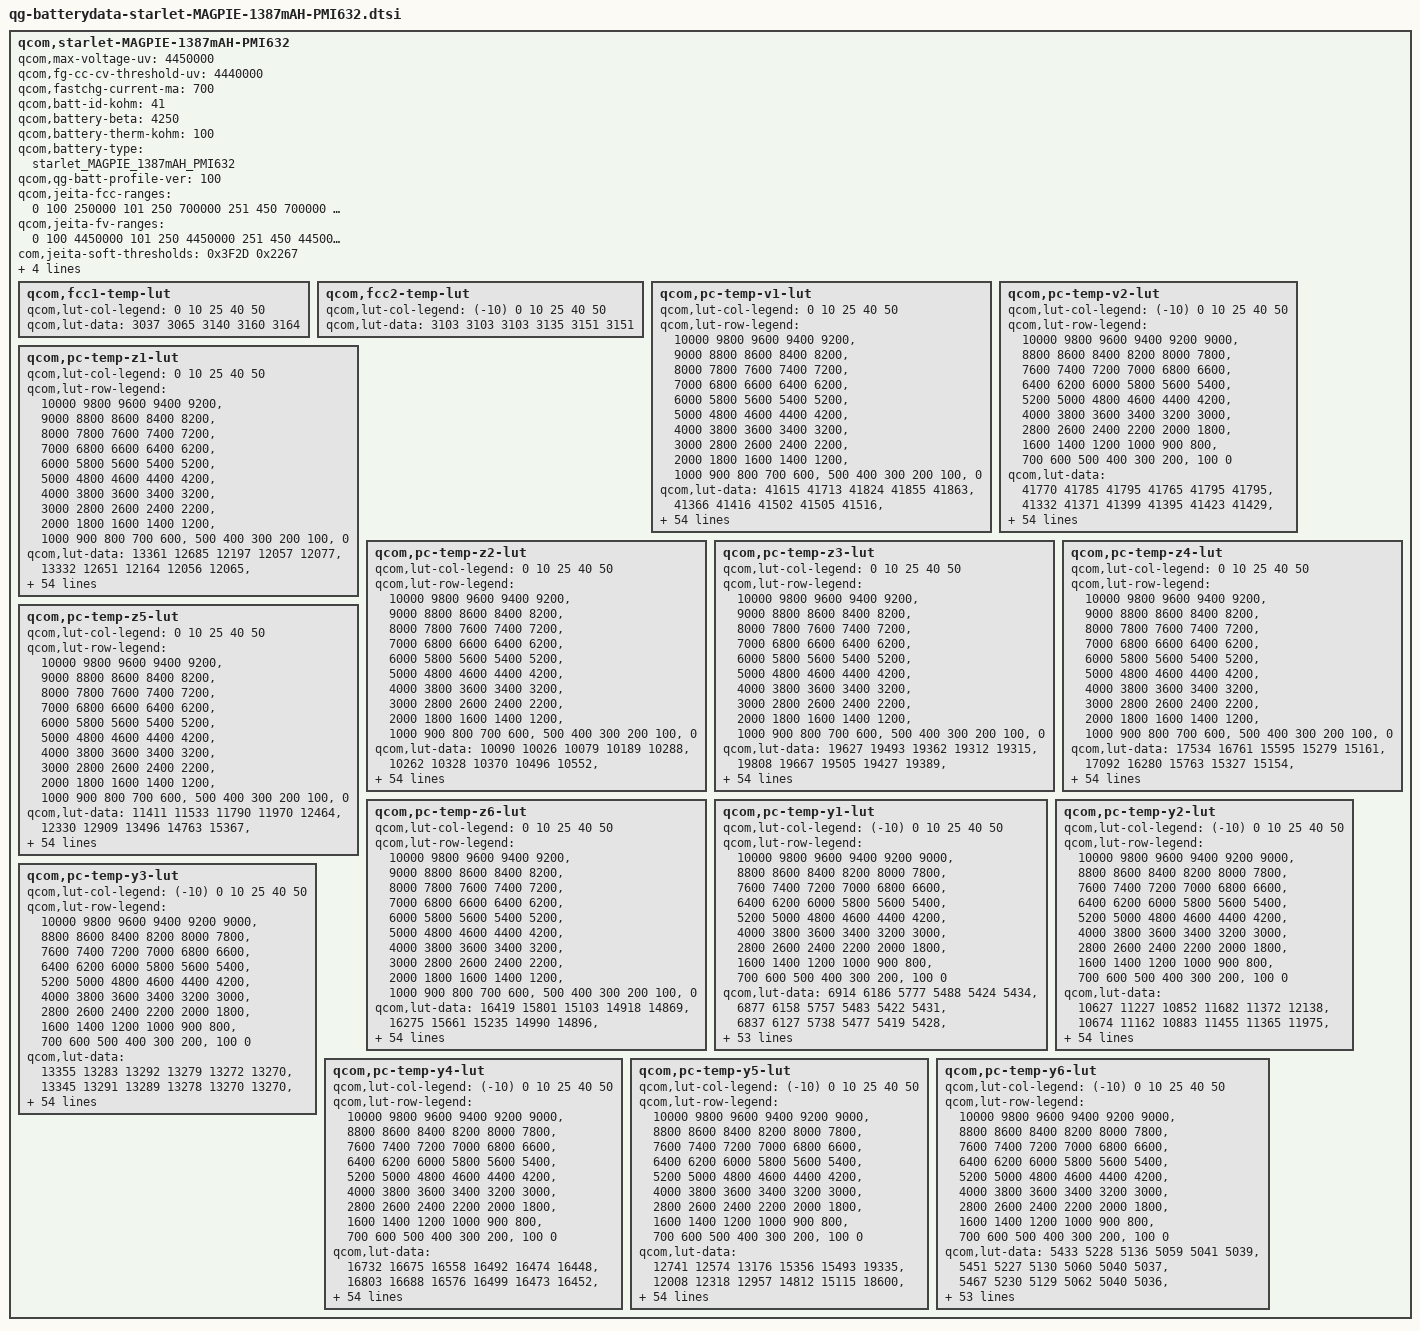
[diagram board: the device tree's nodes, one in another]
qcom,starlet-MAGPIE-1387mAH-PMI632 {
	qcom,max-voltage-uv = <4450000>;
	qcom,fg-cc-cv-threshold-uv = <4440000>;
	qcom,fastchg-current-ma = <700>; // Assumed 0.5C default until step charging takes over
	qcom,batt-id-kohm = <41>; // 220K on board in parallel with 100K on pack and 100K on flex
	qcom,battery-beta = <4250>; // Assumes 25/50 Beta for NCP03WF104F05RL / NTCG064EF104FT
	qcom,battery-therm-kohm = <100>; // // Assumes 100K for NCP03WF104F05RL / NTCG064EF104FT
	qcom,battery-type = "starlet_MAGPIE_1387mAH_PMI632";
	qcom,qg-batt-profile-ver = <100>;

    /*
     * array of 3-tuples in which a 3-tuple describes a range
     *        data of sw-jeita FCC (full charging current) setting.
     * [0]: the low threshold of battery temperature in deci-degree;
     * [1]: the high threshold of battery temperature in deci-degree;
     * [2]: the FCC in uA when battery temperature falls between the low and high thresholds.
     */
	qcom,jeita-fcc-ranges = <0  100 250000
				101 250 700000
				251 450 700000
				451 600 700000>; // Not clear how to specify step charging

	qcom,jeita-fv-ranges = <0  100 4450000
				101 250 4450000
				251 450 4450000
				451 600 4200000>;

	/*
	 * JEITA ADC values are calculated as follows, assuming
	 * a 30K pull-up. r_therm comes from the NTCG063JF103FTB
	 * thermistor datasheet.
	 *   v_adc = v_pull / (r_pullup + r_therm) * r_therm
	 *   v_adc = 1.8 / (30K + r_therm) * r_therm
	 *   adc_code = v_adc * v_fullscale / v_ref
	 *   adc_code = v_adc * 28900 / 1875
	 */
	/* COOL = 20 degC, WARM = 43 degC, need to change to 25C and 45C */
    com,jeita-soft-thresholds = <0x3F2D 0x2267>;
	/* COLD = 0 degC, HOT = 45 degC, need to change to 0C and 60C */
	qcom,jeita-hard-thresholds = <0x5830 0x20C5>;
	/* COOL hys = 23 degC, WARM hys = 42 degC, need to change to 28C and 44C */
    qcom,jeita-soft-hys-thresholds = <0x3BCF 0x247B>;
	qcom,jeita-soft-fcc-ua = <700000 700000>;
	qcom,jeita-soft-fv-uv = <4450000 4200000>;

	qcom,fcc1-temp-lut {
		qcom,lut-col-legend = <0 10 25 40 50>;
		qcom,lut-data = <3037 3065 3140 3160 3164>;
	};

	qcom,fcc2-temp-lut {
		qcom,lut-col-legend = <(-10) 0 10 25 40 50>;
		qcom,lut-data = <3103 3103 3103 3135 3151 3151>;
	};

	qcom,pc-temp-v1-lut {
		qcom,lut-col-legend = <0 10 25 40 50>;
		qcom,lut-row-legend = <10000 9800 9600 9400 9200>,
			<9000 8800 8600 8400 8200>,
			<8000 7800 7600 7400 7200>,
			<7000 6800 6600 6400 6200>,
			<6000 5800 5600 5400 5200>,
			<5000 4800 4600 4400 4200>,
			<4000 3800 3600 3400 3200>,
			<3000 2800 2600 2400 2200>,
			<2000 1800 1600 1400 1200>,
			<1000 900 800 700 600>,
			<500 400 300 200 100>,
			<0>;
		qcom,lut-data = <41615 41713 41824 41855 41863>,
			<41366 41416 41502 41505 41516>,
			<41211 41223 41275 41285 41292>,
			<41103 41110 41126 41142 41147>,
			<41009 41021 41036 41047 41052>,
			<40923 40936 40962 40971 40978>,
			<40834 40853 40870 40885 40894>,
			<40709 40746 40756 40773 40783>,
			<40537 40589 40616 40627 40637>,
			<40342 40393 40431 40441 40450>,
			<40139 40185 40212 40225 40235>,
			<39933 39974 39998 40005 40016>,
			<39739 39770 39793 39795 39808>,
			<39561 39588 39602 39604 39616>,
			<39392 39421 39426 39428 39437>,
			<39228 39264 39263 39264 39270>,
			<39069 39109 39106 39106 39110>,
			<38911 38954 38950 38948 38951>,
			<38748 38791 38788 38785 38788>,
			<38575 38620 38616 38612 38616>,
			<38392 38442 38435 38431 38435>,
			<38199 38251 38243 38238 38242>,
			<38000 38051 38027 38020 38025>,
			<37799 37842 37767 37736 37743>,
			<37601 37623 37474 37413 37422>,
			<37408 37388 37198 37161 37177>,
			<37222 37143 36971 36985 37017>,
			<37038 36917 36798 36844 36886>,
			<36854 36720 36673 36725 36763>,
			<36681 36566 36574 36623 36649>,
			<36525 36453 36485 36524 36540>,
			<36386 36361 36400 36424 36434>,
			<36273 36279 36316 36324 36332>,
			<36184 36202 36223 36226 36233>,
			<36103 36126 36125 36129 36134>,
			<36023 36044 36028 36029 36032>,
			<35946 35957 35935 35927 35926>,
			<35859 35862 35836 35816 35808>,
			<35761 35758 35721 35685 35671>,
			<35644 35638 35583 35531 35510>,
			<35497 35484 35413 35350 35323>,
			<35298 35274 35187 35123 35091>,
			<35069 35035 34931 34865 34832>,
			<34815 34775 34652 34582 34550>,
			<34563 34508 34373 34312 34288>,
			<34327 34255 34140 34096 34082>,
			<34243 34157 34053 34013 34002>,
			<34178 34082 33978 33940 33929>,
			<34095 34010 33909 33871 33861>,
			<34025 33939 33843 33796 33783>,
			<33928 33853 33741 33687 33668>,
			<33755 33687 33480 33392 33349>,
			<33320 33271 32951 32858 32834>,
			<32608 32557 32233 32164 32157>,
			<31577 31562 31207 31193 31221>,
			<30000 30000 30000 30000 30000>;
	};

	qcom,pc-temp-v2-lut {
		qcom,lut-col-legend = <(-10) 0 10 25 40 50>;
		qcom,lut-row-legend = <10000 9800 9600 9400 9200 9000>,
			<8800 8600 8400 8200 8000 7800>,
			<7600 7400 7200 7000 6800 6600>,
			<6400 6200 6000 5800 5600 5400>,
			<5200 5000 4800 4600 4400 4200>,
			<4000 3800 3600 3400 3200 3000>,
			<2800 2600 2400 2200 2000 1800>,
			<1600 1400 1200 1000 900 800>,
			<700 600 500 400 300 200>,
			<100 0>;
		qcom,lut-data = <41770 41785 41795 41765 41795 41795>,
			<41332 41371 41399 41395 41423 41429>,
			<41005 41062 41099 41115 41141 41152>,
			<40849 40909 40947 40968 40992 41003>,
			<40775 40834 40868 40889 40911 40921>,
			<40706 40765 40797 40814 40834 40843>,
			<40611 40669 40704 40715 40735 40744>,
			<40497 40556 40598 40600 40622 40630>,
			<40353 40416 40464 40454 40477 40484>,
			<40148 40225 40272 40255 40276 40282>,
			<39912 40010 40054 40038 40057 40061>,
			<39681 39808 39844 39830 39848 39851>,
			<39443 39610 39632 39624 39640 39642>,
			<39221 39423 39439 39435 39450 39453>,
			<39023 39253 39271 39268 39279 39284>,
			<38839 39084 39114 39108 39116 39122>,
			<38660 38887 38961 38949 38957 38962>,
			<38486 38662 38810 38792 38801 38804>,
			<38308 38432 38632 38628 38637 38638>,
			<38119 38208 38394 38459 38464 38466>,
			<37923 37986 38117 38275 38280 38284>,
			<37720 37768 37853 38047 38069 38074>,
			<37511 37554 37611 37758 37814 37820>,
			<37304 37348 37388 37464 37542 37550>,
			<37102 37151 37185 37211 37270 37286>,
			<36907 36962 36996 36999 37036 37057>,
			<36730 36790 36827 36829 36861 36883>,
			<36575 36637 36677 36683 36718 36738>,
			<36436 36500 36543 36553 36590 36608>,
			<36311 36376 36422 36436 36473 36491>,
			<36199 36263 36314 36330 36367 36385>,
			<36093 36157 36212 36230 36266 36285>,
			<35988 36056 36113 36134 36168 36191>,
			<35882 35959 36015 36040 36069 36095>,
			<35769 35860 35916 35945 35966 35993>,
			<35647 35759 35814 35848 35859 35878>,
			<35515 35655 35711 35749 35740 35742>,
			<35367 35545 35600 35636 35608 35589>,
			<35199 35427 35480 35504 35458 35426>,
			<35004 35292 35343 35345 35289 35256>,
			<34792 35118 35175 35156 35102 35074>,
			<34578 34879 34954 34934 34890 34867>,
			<34374 34589 34685 34673 34631 34614>,
			<34192 34300 34382 34338 34319 34306>,
			<34009 34027 34080 34072 34074 34067>,
			<33789 33826 33878 33898 33902 33899>,
			<33671 33733 33790 33819 33829 33831>,
			<33553 33640 33703 33745 33755 33759>,
			<33431 33542 33616 33665 33677 33680>,
			<33284 33414 33516 33561 33573 33577>,
			<33064 33198 33346 33353 33355 33374>,
			<32675 32768 32959 32867 32892 32927>,
			<32097 32131 32325 32193 32267 32323>,
			<31375 31346 31525 31398 31526 31595>,
			<30529 30407 30595 30493 30691 30786>,
			<29490 29308 29749 29512 29716 29867>;
	};

	qcom,pc-temp-z1-lut {
		qcom,lut-col-legend = <0 10 25 40 50>;
		qcom,lut-row-legend = <10000 9800 9600 9400 9200>,
			<9000 8800 8600 8400 8200>,
			<8000 7800 7600 7400 7200>,
			<7000 6800 6600 6400 6200>,
			<6000 5800 5600 5400 5200>,
			<5000 4800 4600 4400 4200>,
			<4000 3800 3600 3400 3200>,
			<3000 2800 2600 2400 2200>,
			<2000 1800 1600 1400 1200>,
			<1000 900 800 700 600>,
			<500 400 300 200 100>,
			<0>;
		qcom,lut-data = <13361 12685 12197 12057 12077>,
			<13332 12651 12164 12056 12065>,
			<13292 12616 12145 12048 12061>,
			<13244 12584 12131 12041 12060>,
			<13199 12554 12122 12036 12057>,
			<13156 12526 12114 12031 12054>,
			<13116 12498 12105 12027 12051>,
			<13077 12472 12095 12024 12048>,
			<13037 12447 12086 12022 12046>,
			<12996 12426 12080 12019 12045>,
			<12956 12410 12075 12018 12045>,
			<12920 12396 12073 12018 12045>,
			<12893 12386 12072 12019 12045>,
			<12875 12381 12072 12019 12044>,
			<12862 12381 12072 12018 12044>,
			<12853 12382 12072 12018 12045>,
			<12850 12382 12072 12018 12045>,
			<12852 12383 12073 12019 12045>,
			<12860 12384 12073 12019 12046>,
			<12867 12386 12074 12020 12047>,
			<12874 12390 12075 12020 12047>,
			<12881 12393 12078 12022 12049>,
			<12891 12396 12080 12024 12050>,
			<12901 12400 12081 12025 12052>,
			<12909 12404 12083 12027 12053>,
			<12918 12408 12084 12028 12055>,
			<12927 12412 12086 12030 12057>,
			<12937 12416 12088 12032 12058>,
			<12947 12418 12090 12034 12059>,
			<12956 12421 12092 12036 12060>,
			<12962 12423 12095 12039 12062>,
			<12968 12427 12098 12042 12065>,
			<12974 12432 12103 12045 12069>,
			<12981 12437 12108 12047 12071>,
			<12989 12444 12115 12050 12072>,
			<13003 12453 12122 12053 12074>,
			<13022 12467 12129 12057 12076>,
			<13049 12485 12137 12062 12079>,
			<13088 12508 12148 12068 12083>,
			<13138 12538 12162 12075 12089>,
			<13197 12574 12178 12084 12096>,
			<13268 12621 12197 12096 12105>,
			<13354 12675 12220 12109 12116>,
			<13464 12737 12247 12125 12128>,
			<13596 12829 12288 12148 12144>,
			<13679 12892 12323 12171 12163>,
			<13710 12912 12339 12181 12171>,
			<13740 12935 12358 12192 12181>,
			<13786 12960 12370 12205 12191>,
			<13810 12988 12388 12217 12200>,
			<13845 13012 12408 12231 12211>,
			<13917 13048 12429 12248 12226>,
			<13950 13099 12455 12284 12240>,
			<14029 13131 12493 12293 12264>,
			<14029 13131 12493 12293 12264>,
			<14029 13131 12493 12293 12264>;
	};

	qcom,pc-temp-z2-lut {
		qcom,lut-col-legend = <0 10 25 40 50>;
		qcom,lut-row-legend = <10000 9800 9600 9400 9200>,
			<9000 8800 8600 8400 8200>,
			<8000 7800 7600 7400 7200>,
			<7000 6800 6600 6400 6200>,
			<6000 5800 5600 5400 5200>,
			<5000 4800 4600 4400 4200>,
			<4000 3800 3600 3400 3200>,
			<3000 2800 2600 2400 2200>,
			<2000 1800 1600 1400 1200>,
			<1000 900 800 700 600>,
			<500 400 300 200 100>,
			<0>;
		qcom,lut-data = <10090 10026 10079 10189 10288>,
			<10262 10328 10370 10496 10552>,
			<10367 10459 10610 11089 11207>,
			<10441 10523 10724 11623 11861>,
			<10470 10559 10778 11794 12114>,
			<10470 10566 10809 11739 12063>,
			<10466 10560 10816 11598 11897>,
			<10459 10543 10814 11418 11701>,
			<10447 10483 10807 11226 11517>,
			<10437 10411 10758 11038 11339>,
			<10456 10377 10686 10862 11103>,
			<10497 10369 10628 10737 10829>,
			<10525 10369 10527 10675 10621>,
			<10541 10388 10411 10609 10518>,
			<10555 10430 10405 10499 10505>,
			<10579 10470 10435 10451 10565>,
			<10605 10501 10416 10501 10649>,
			<10605 10531 10365 10551 10702>,
			<10572 10560 10380 10579 10740>,
			<10535 10585 10417 10592 10770>,
			<10511 10608 10446 10598 10789>,
			<10497 10633 10476 10606 10800>,
			<10495 10658 10543 10626 10815>,
			<10502 10685 10696 10754 10940>,
			<10516 10716 10901 10980 11183>,
			<10537 10755 10999 11124 11274>,
			<10563 10801 10987 11181 11093>,
			<10592 10831 10967 11205 10883>,
			<10628 10842 10972 11133 10866>,
			<10659 10852 10980 10964 10920>,
			<10675 10861 10940 10806 10908>,
			<10687 10870 10820 10655 10656>,
			<10693 10882 10740 10516 10386>,
			<10697 10909 10766 10429 10364>,
			<10702 10952 10812 10368 10431>,
			<10731 10978 10790 10353 10523>,
			<10787 10991 10695 10454 10690>,
			<10813 10986 10631 10612 10851>,
			<10780 10941 10735 10730 10884>,
			<10725 10880 10990 10837 10892>,
			<10693 10838 11103 10919 10893>,
			<10674 10807 11099 10983 10853>,
			<10675 10790 11084 10981 10786>,
			<10702 10767 11027 10690 10719>,
			<10922 10904 10979 10627 10676>,
			<10862 10803 10878 10545 10562>,
			<10899 10737 10766 10555 10475>,
			<11252 10634 10647 10377 10401>,
			<10622 10537 10537 10333 10450>,
			<10513 10427 10446 10335 10521>,
			<10436 10345 10459 10430 10622>,
			<10378 10289 10361 10130 10169>,
			<10328 10167 10128 10044 10017>,
			<10133 9996 9841 9841 9991>,
			<10133 9996 9841 9841 9991>,
			<10133 9996 9841 9841 9991>;
	};

	qcom,pc-temp-z3-lut {
		qcom,lut-col-legend = <0 10 25 40 50>;
		qcom,lut-row-legend = <10000 9800 9600 9400 9200>,
			<9000 8800 8600 8400 8200>,
			<8000 7800 7600 7400 7200>,
			<7000 6800 6600 6400 6200>,
			<6000 5800 5600 5400 5200>,
			<5000 4800 4600 4400 4200>,
			<4000 3800 3600 3400 3200>,
			<3000 2800 2600 2400 2200>,
			<2000 1800 1600 1400 1200>,
			<1000 900 800 700 600>,
			<500 400 300 200 100>,
			<0>;
		qcom,lut-data = <19627 19493 19362 19312 19315>,
			<19808 19667 19505 19427 19389>,
			<19829 19717 19536 19440 19402>,
			<19824 19698 19541 19436 19399>,
			<19822 19671 19528 19431 19392>,
			<19826 19661 19512 19434 19392>,
			<19836 19659 19512 19442 19398>,
			<19844 19659 19528 19454 19409>,
			<19847 19667 19543 19463 19420>,
			<19842 19685 19553 19466 19426>,
			<19806 19694 19563 19462 19420>,
			<19749 19688 19559 19448 19402>,
			<19697 19673 19509 19426 19375>,
			<19649 19636 19445 19397 19351>,
			<19624 19575 19417 19367 19338>,
			<19639 19527 19401 19346 19333>,
			<19664 19509 19378 19335 19327>,
			<19657 19501 19353 19326 19321>,
			<19637 19495 19345 19321 19314>,
			<19619 19484 19344 19318 19310>,
			<19610 19468 19344 19318 19309>,
			<19607 19461 19345 19323 19312>,
			<19605 19469 19357 19330 19318>,
			<19601 19490 19397 19348 19334>,
			<19602 19520 19446 19373 19353>,
			<19613 19556 19465 19383 19358>,
			<19631 19585 19460 19378 19346>,
			<19661 19593 19450 19368 19330>,
			<19701 19589 19435 19346 19320>,
			<19721 19580 19412 19319 19314>,
			<19721 19564 19383 19311 19315>,
			<19716 19540 19349 19330 19326>,
			<19704 19513 19330 19352 19336>,
			<19679 19475 19355 19354 19336>,
			<19649 19445 19412 19346 19329>,
			<19612 19442 19432 19337 19322>,
			<19571 19450 19401 19330 19316>,
			<19554 19460 19369 19325 19313>,
			<19566 19466 19374 19325 19313>,
			<19591 19474 19399 19326 19314>,
			<19623 19489 19412 19330 19315>,
			<19664 19519 19412 19349 19321>,
			<19674 19533 19412 19360 19325>,
			<19661 19534 19413 19351 19325>,
			<19555 19479 19405 19343 19322>,
			<19565 19489 19408 19350 19325>,
			<19578 19506 19420 19359 19333>,
			<19597 19517 19438 19356 19329>,
			<19600 19536 19447 19351 19325>,
			<19613 19546 19431 19347 19315>,
			<19640 19555 19432 19343 19314>,
			<19671 19577 19491 19374 19357>,
			<19726 19622 19556 19424 19368>,
			<19768 19708 19527 19402 19347>,
			<19768 19708 19527 19402 19347>,
			<19768 19708 19527 19402 19347>;
	};

	qcom,pc-temp-z4-lut {
		qcom,lut-col-legend = <0 10 25 40 50>;
		qcom,lut-row-legend = <10000 9800 9600 9400 9200>,
			<9000 8800 8600 8400 8200>,
			<8000 7800 7600 7400 7200>,
			<7000 6800 6600 6400 6200>,
			<6000 5800 5600 5400 5200>,
			<5000 4800 4600 4400 4200>,
			<4000 3800 3600 3400 3200>,
			<3000 2800 2600 2400 2200>,
			<2000 1800 1600 1400 1200>,
			<1000 900 800 700 600>,
			<500 400 300 200 100>,
			<0>;
		qcom,lut-data = <17534 16761 15595 15279 15161>,
			<17092 16280 15763 15327 15154>,
			<16712 15957 15472 15171 15054>,
			<16389 15745 15269 15058 14972>,
			<16158 15597 15196 14999 14924>,
			<15995 15498 15146 14959 14894>,
			<15865 15425 15095 14924 14867>,
			<15749 15360 15040 14888 14838>,
			<15647 15291 14987 14853 14805>,
			<15568 15220 14934 14824 14778>,
			<15509 15153 14886 14804 14766>,
			<15461 15095 14861 14791 14766>,
			<15420 15054 14875 14786 14767>,
			<15382 15037 14902 14792 14771>,
			<15337 15032 14903 14801 14769>,
			<15245 15028 14891 14802 14756>,
			<15143 15018 14885 14792 14739>,
			<15101 14991 14882 14777 14727>,
			<15086 14965 14871 14763 14717>,
			<15078 14952 14849 14746 14705>,
			<15069 14943 14826 14731 14694>,
			<15058 14933 14808 14719 14687>,
			<15047 14908 14796 14716 14685>,
			<15037 14872 14794 14758 14728>,
			<15024 14847 14815 14843 14820>,
			<15003 14840 14865 14889 14866>,
			<14975 14855 14928 14898 14868>,
			<14947 14893 14958 14903 14868>,
			<14926 14946 14963 14908 14866>,
			<14921 14979 14963 14912 14854>,
			<14933 14985 14966 14907 14833>,
			<14960 14986 14973 14866 14793>,
			<14979 14989 14975 14809 14750>,
			<14987 14995 14928 14779 14727>,
			<14996 14999 14831 14760 14711>,
			<15008 14987 14789 14749 14706>,
			<15023 14943 14791 14740 14708>,
			<15028 14899 14794 14735 14711>,
			<14999 14868 14786 14743 14718>,
			<14952 14846 14771 14769 14737>,
			<14931 14843 14770 14787 14752>,
			<14936 14875 14824 14787 14759>,
			<14951 14903 14866 14791 14767>,
			<14965 14914 14875 14817 14782>,
			<14920 14877 14844 14809 14778>,
			<14943 14896 14842 14798 14767>,
			<14953 14904 14836 14782 14747>,
			<14926 14904 14811 14767 14729>,
			<14948 14883 14779 14741 14705>,
			<14926 14858 14768 14719 14692>,
			<14915 14845 14770 14728 14702>,
			<14946 14880 14800 14779 14716>,
			<15030 14954 14803 14746 14717>,
			<15082 14946 14842 14768 14730>,
			<15082 14946 14842 14768 14730>,
			<15082 14946 14842 14768 14730>;
	};

	qcom,pc-temp-z5-lut {
		qcom,lut-col-legend = <0 10 25 40 50>;
		qcom,lut-row-legend = <10000 9800 9600 9400 9200>,
			<9000 8800 8600 8400 8200>,
			<8000 7800 7600 7400 7200>,
			<7000 6800 6600 6400 6200>,
			<6000 5800 5600 5400 5200>,
			<5000 4800 4600 4400 4200>,
			<4000 3800 3600 3400 3200>,
			<3000 2800 2600 2400 2200>,
			<2000 1800 1600 1400 1200>,
			<1000 900 800 700 600>,
			<500 400 300 200 100>,
			<0>;
		qcom,lut-data = <11411 11533 11790 11970 12464>,
			<12330 12909 13496 14763 15367>,
			<12887 13666 14644 15428 16297>,
			<13273 13967 15113 15681 16423>,
			<13587 14173 15216 15830 16389>,
			<13870 14331 15291 16282 16664>,
			<14131 14454 15455 16928 17212>,
			<14344 14585 15720 17526 18046>,
			<14493 14792 16038 18155 19237>,
			<14540 15207 16630 18659 20111>,
			<14418 15636 17648 18886 20152>,
			<14214 15920 18006 18815 19222>,
			<14039 15995 16670 18377 17585>,
			<13897 15700 14874 17013 16102>,
			<13882 14980 14368 15376 15372>,
			<14628 14383 14261 14525 15440>,
			<15604 14273 13873 14336 15580>,
			<15780 14450 13321 14253 15449>,
			<15661 14673 13262 14248 15243>,
			<15502 14737 13477 14430 15304>,
			<15494 14709 13776 14916 15799>,
			<15643 14786 14175 15891 17092>,
			<15821 15396 16947 17615 19518>,
			<16005 17039 27190 23737 25139>,
			<16287 20476 40274 32848 31569>,
			<16972 27739 44509 35607 32541>,
			<18375 36563 39959 30657 26659>,
			<21637 40442 33789 24087 19409>,
			<28321 39907 28071 19089 15795>,
			<33725 37898 22849 15180 13814>,
			<34854 33756 18760 13844 13278>,
			<34769 28462 15604 13982 13881>,
			<33328 24098 13964 14297 14900>,
			<29210 20065 14645 14748 15897>,
			<24399 17117 16793 15307 16802>,
			<20687 16254 17744 15733 17221>,
			<17545 15977 16943 16295 17456>,
			<16305 15909 16083 16834 17596>,
			<16789 16491 17126 16770 17286>,
			<18024 17916 20669 16258 16218>,
			<20149 19602 22387 15907 15446>,
			<24030 21772 19461 16137 15226>,
			<25506 22188 16690 16065 15018>,
			<24140 20992 16159 14782 14388>,
			<23526 20341 16729 14724 14345>,
			<23417 20107 16873 15022 14532>,
			<22635 20132 17047 15430 15075>,
			<22438 19678 18183 15403 15362>,
			<22034 20540 20082 15982 16079>,
			<22203 21728 19986 17502 16921>,
			<23594 22811 20708 17161 16241>,
			<23292 22010 20190 14885 16248>,
			<21108 17999 20379 19180 16786>,
			<17625 18473 18104 15904 15653>,
			<17625 18473 18104 15904 15653>,
			<17625 18473 18104 15904 15653>;
	};

	qcom,pc-temp-z6-lut {
		qcom,lut-col-legend = <0 10 25 40 50>;
		qcom,lut-row-legend = <10000 9800 9600 9400 9200>,
			<9000 8800 8600 8400 8200>,
			<8000 7800 7600 7400 7200>,
			<7000 6800 6600 6400 6200>,
			<6000 5800 5600 5400 5200>,
			<5000 4800 4600 4400 4200>,
			<4000 3800 3600 3400 3200>,
			<3000 2800 2600 2400 2200>,
			<2000 1800 1600 1400 1200>,
			<1000 900 800 700 600>,
			<500 400 300 200 100>,
			<0>;
		qcom,lut-data = <16419 15801 15103 14918 14869>,
			<16275 15661 15235 14990 14896>,
			<16107 15538 15131 14941 14869>,
			<15933 15426 15046 14887 14831>,
			<15807 15337 15002 14856 14806>,
			<15723 15281 14972 14840 14792>,
			<15658 15241 14951 14828 14783>,
			<15602 15209 14935 14819 14776>,
			<15553 15181 14920 14810 14770>,
			<15502 15156 14905 14800 14762>,
			<15448 15130 14890 14787 14752>,
			<15393 15102 14872 14773 14740>,
			<15345 15072 14850 14760 14728>,
			<15300 15040 14831 14746 14717>,
			<15261 15009 14815 14734 14707>,
			<15227 14985 14801 14722 14698>,
			<15197 14967 14787 14711 14688>,
			<15174 14952 14773 14700 14679>,
			<15159 14939 14760 14690 14670>,
			<15148 14927 14750 14681 14662>,
			<15141 14915 14741 14676 14658>,
			<15136 14907 14735 14674 14657>,
			<15131 14903 14735 14674 14659>,
			<15127 14902 14751 14702 14685>,
			<15125 14903 14790 14754 14735>,
			<15123 14914 14826 14777 14758>,
			<15122 14939 14846 14777 14753>,
			<15125 14965 14853 14775 14746>,
			<15136 14983 14849 14770 14738>,
			<15148 14991 14837 14759 14732>,
			<15158 14987 14824 14749 14724>,
			<15165 14976 14813 14741 14715>,
			<15166 14964 14802 14732 14704>,
			<15159 14951 14794 14722 14694>,
			<15148 14937 14787 14710 14683>,
			<15139 14925 14778 14700 14677>,
			<15129 14914 14763 14693 14674>,
			<15125 14906 14751 14688 14673>,
			<15127 14904 14750 14690 14675>,
			<15133 14903 14756 14702 14684>,
			<15147 14911 14768 14715 14693>,
			<15188 14949 14795 14727 14701>,
			<15226 14984 14817 14738 14709>,
			<15253 15005 14829 14748 14719>,
			<15228 14986 14820 14744 14717>,
			<15268 15018 14829 14747 14719>,
			<15289 15039 14837 14748 14716>,
			<15302 15053 14839 14743 14709>,
			<15319 15061 14836 14733 14698>,
			<15327 15064 14827 14723 14689>,
			<15349 15072 14834 14728 14694>,
			<15398 15112 14886 14774 14731>,
			<15482 15185 14933 14795 14743>,
			<15551 15242 14947 14801 14745>,
			<15551 15242 14947 14801 14745>,
			<15551 15242 14947 14801 14745>;
	};

	qcom,pc-temp-y1-lut {
		qcom,lut-col-legend = <(-10) 0 10 25 40 50>;
		qcom,lut-row-legend = <10000 9800 9600 9400 9200 9000>,
			<8800 8600 8400 8200 8000 7800>,
			<7600 7400 7200 7000 6800 6600>,
			<6400 6200 6000 5800 5600 5400>,
			<5200 5000 4800 4600 4400 4200>,
			<4000 3800 3600 3400 3200 3000>,
			<2800 2600 2400 2200 2000 1800>,
			<1600 1400 1200 1000 900 800>,
			<700 600 500 400 300 200>,
			<100 0>;
		qcom,lut-data = <6914 6186 5777 5488 5424 5434>,
			<6877 6158 5757 5483 5422 5431>,
			<6837 6127 5738 5477 5419 5428>,
			<6799 6097 5720 5470 5416 5425>,
			<6766 6072 5704 5464 5414 5423>,
			<6742 6054 5692 5461 5411 5421>,
			<6726 6045 5682 5459 5408 5421>,
			<6714 6039 5674 5459 5406 5421>,
			<6703 6031 5668 5457 5405 5421>,
			<6693 6019 5665 5455 5408 5420>,
			<6685 6009 5662 5454 5412 5419>,
			<6678 6004 5658 5453 5412 5419>,
			<6668 6002 5655 5452 5412 5419>,
			<6661 6000 5652 5451 5411 5419>,
			<6661 6000 5650 5451 5410 5418>,
			<6663 6000 5648 5451 5409 5418>,
			<6671 6001 5648 5451 5409 5418>,
			<6685 6002 5649 5452 5409 5420>,
			<6688 6003 5650 5453 5409 5422>,
			<6680 6002 5652 5454 5411 5424>,
			<6676 6003 5654 5454 5412 5425>,
			<6685 6003 5655 5456 5412 5424>,
			<6696 6002 5656 5457 5412 5422>,
			<6696 6001 5657 5459 5411 5422>,
			<6688 6001 5657 5459 5412 5423>,
			<6686 6005 5656 5459 5413 5425>,
			<6696 6010 5656 5459 5414 5425>,
			<6706 6016 5657 5458 5415 5424>,
			<6712 6020 5659 5457 5415 5424>,
			<6713 6023 5660 5457 5415 5425>,
			<6719 6025 5662 5459 5416 5429>,
			<6730 6029 5666 5462 5417 5431>,
			<6745 6036 5672 5466 5420 5431>,
			<6762 6045 5678 5469 5423 5431>,
			<6784 6054 5684 5471 5423 5432>,
			<6806 6065 5690 5472 5421 5432>,
			<6824 6081 5698 5474 5420 5433>,
			<6840 6102 5708 5476 5422 5433>,
			<6859 6125 5721 5482 5426 5435>,
			<6884 6150 5737 5490 5431 5437>,
			<6915 6176 5757 5498 5436 5441>,
			<6953 6199 5782 5508 5441 5446>,
			<6996 6223 5813 5521 5449 5453>,
			<7030 6259 5847 5541 5460 5459>,
			<7071 6304 5885 5565 5472 5469>,
			<7219 6342 5936 5595 5487 5483>,
			<7283 6377 5951 5611 5498 5488>,
			<7360 6410 5979 5633 5508 5494>,
			<7411 6448 5994 5655 5519 5501>,
			<7538 6498 6003 5673 5531 5511>,
			<7605 6565 6030 5693 5543 5521>,
			<7593 6647 6063 5712 5557 5525>,
			<7671 6680 6095 5738 5575 5540>,
			<7776 6763 6142 5766 5595 5553>,
			<7776 6763 6142 5766 5595 5553>,
			<7776 6763 6142 5766 5595 5553>;
	};

	qcom,pc-temp-y2-lut {
		qcom,lut-col-legend = <(-10) 0 10 25 40 50>;
		qcom,lut-row-legend = <10000 9800 9600 9400 9200 9000>,
			<8800 8600 8400 8200 8000 7800>,
			<7600 7400 7200 7000 6800 6600>,
			<6400 6200 6000 5800 5600 5400>,
			<5200 5000 4800 4600 4400 4200>,
			<4000 3800 3600 3400 3200 3000>,
			<2800 2600 2400 2200 2000 1800>,
			<1600 1400 1200 1000 900 800>,
			<700 600 500 400 300 200>,
			<100 0>;
		qcom,lut-data = <10627 11227 10852 11682 11372 12138>,
			<10674 11162 10883 11455 11365 11975>,
			<10720 11108 10924 11253 11333 11734>,
			<10763 11067 10967 11089 11280 11475>,
			<10805 11039 11004 10977 11210 11258>,
			<10843 11026 11028 10930 11127 11140>,
			<10880 11033 11042 10963 11003 11101>,
			<10915 11054 11064 11039 10872 11073>,
			<10940 11078 11094 11085 10850 11052>,
			<10958 11122 11138 11112 10962 11031>,
			<10976 11168 11192 11134 11084 11017>,
			<11002 11190 11262 11193 11136 11039>,
			<11032 11204 11356 11273 11175 11118>,
			<11056 11212 11424 11307 11187 11177>,
			<11072 11218 11459 11338 11264 11276>,
			<11088 11223 11479 11381 11367 11336>,
			<11109 11233 11471 11438 11423 11320>,
			<11138 11248 11440 11514 11477 11284>,
			<11165 11264 11421 11602 11498 11270>,
			<11184 11286 11416 11719 11510 11368>,
			<11201 11328 11413 11799 11531 11519>,
			<11224 11370 11424 11804 11658 11612>,
			<11256 11404 11472 11773 11872 11645>,
			<11290 11430 11536 11719 11918 11609>,
			<11320 11451 11592 11631 11696 11544>,
			<11348 11481 11648 11564 11469 11546>,
			<11370 11525 11705 11575 11481 11598>,
			<11385 11587 11758 11680 11714 11641>,
			<11397 11651 11807 11798 11907 11701>,
			<11404 11692 11840 11822 11938 11833>,
			<11408 11707 11860 11810 11947 11981>,
			<11405 11706 11876 11890 11968 12137>,
			<11389 11699 11893 12048 11972 12279>,
			<11351 11688 11913 12141 11959 12323>,
			<11299 11671 11917 12175 11988 12296>,
			<11253 11649 11902 12172 12004 12275>,
			<11216 11626 11886 12152 11982 12216>,
			<11178 11601 11866 12113 11898 12035>,
			<11115 11571 11831 12046 11746 11835>,
			<10996 11526 11773 11945 11559 11757>,
			<10809 11447 11696 11841 11479 11733>,
			<10494 11285 11588 11730 11517 11694>,
			<10078 10996 11411 11595 11583 11600>,
			<9838 10528 11045 11404 11626 11405>,
			<9667 10020 10519 11126 11403 11245>,
			<9656 9777 10213 10759 10962 11131>,
			<9655 9681 10090 10704 10906 11099>,
			<9654 9659 9960 10640 10830 11101>,
			<9653 9657 9799 10616 10869 11044>,
			<9653 9655 9706 10521 10922 10835>,
			<9653 9655 9673 10289 10664 10776>,
			<9652 9654 9661 10114 10562 10732>,
			<9652 9653 9657 10130 10551 10674>,
			<9652 9653 9656 10208 10612 10691>,
			<9652 9653 9656 10208 10612 10691>,
			<9652 9653 9656 10208 10612 10691>;
	};

	qcom,pc-temp-y3-lut {
		qcom,lut-col-legend = <(-10) 0 10 25 40 50>;
		qcom,lut-row-legend = <10000 9800 9600 9400 9200 9000>,
			<8800 8600 8400 8200 8000 7800>,
			<7600 7400 7200 7000 6800 6600>,
			<6400 6200 6000 5800 5600 5400>,
			<5200 5000 4800 4600 4400 4200>,
			<4000 3800 3600 3400 3200 3000>,
			<2800 2600 2400 2200 2000 1800>,
			<1600 1400 1200 1000 900 800>,
			<700 600 500 400 300 200>,
			<100 0>;
		qcom,lut-data = <13355 13283 13292 13279 13272 13270>,
			<13345 13291 13289 13278 13270 13270>,
			<13342 13298 13287 13278 13270 13270>,
			<13344 13306 13288 13279 13270 13270>,
			<13350 13312 13289 13280 13271 13270>,
			<13358 13317 13291 13282 13272 13270>,
			<13375 13320 13295 13285 13274 13272>,
			<13397 13322 13303 13288 13277 13276>,
			<13404 13324 13310 13290 13279 13278>,
			<13404 13328 13317 13294 13283 13279>,
			<13404 13334 13321 13299 13287 13280>,
			<13401 13344 13321 13301 13289 13282>,
			<13390 13359 13316 13302 13291 13284>,
			<13379 13371 13313 13304 13291 13286>,
			<13370 13378 13316 13307 13289 13288>,
			<13363 13382 13323 13310 13288 13289>,
			<13363 13381 13331 13310 13289 13287>,
			<13364 13372 13339 13309 13291 13284>,
			<13365 13360 13342 13309 13294 13283>,
			<13368 13349 13338 13314 13299 13287>,
			<13369 13337 13329 13322 13305 13294>,
			<13369 13328 13319 13321 13307 13297>,
			<13369 13323 13308 13309 13304 13292>,
			<13370 13321 13299 13295 13296 13285>,
			<13370 13322 13296 13284 13281 13276>,
			<13368 13324 13296 13277 13271 13270>,
			<13367 13324 13296 13275 13271 13270>,
			<13370 13325 13297 13277 13273 13269>,
			<13376 13328 13298 13279 13275 13269>,
			<13382 13329 13301 13280 13274 13269>,
			<13388 13329 13303 13279 13274 13270>,
			<13395 13330 13306 13280 13274 13272>,
			<13401 13333 13309 13283 13275 13275>,
			<13406 13337 13312 13286 13276 13276>,
			<13410 13342 13315 13288 13277 13277>,
			<13415 13346 13318 13290 13278 13277>,
			<13421 13351 13322 13293 13279 13276>,
			<13429 13357 13325 13295 13279 13275>,
			<13438 13365 13328 13297 13277 13273>,
			<13443 13373 13331 13296 13275 13273>,
			<13444 13376 13333 13293 13274 13274>,
			<13471 13377 13330 13289 13274 13276>,
			<13645 13378 13324 13285 13275 13277>,
			<14225 13400 13319 13282 13277 13273>,
			<15863 13510 13315 13284 13279 13272>,
			<19803 14087 13358 13295 13282 13274>,
			<22599 14558 13400 13302 13285 13282>,
			<26952 15509 13484 13314 13286 13286>,
			<32841 17036 13634 13327 13295 13288>,
			<39643 18833 13893 13333 13302 13289>,
			<46932 20879 14312 13338 13297 13287>,
			<54706 23401 14999 13346 13295 13289>,
			<60958 25867 15762 13383 13310 13295>,
			<63218 27480 16623 13444 13327 13302>,
			<63218 27480 16623 13444 13327 13302>,
			<63218 27480 16623 13444 13327 13302>;
	};

	qcom,pc-temp-y4-lut {
		qcom,lut-col-legend = <(-10) 0 10 25 40 50>;
		qcom,lut-row-legend = <10000 9800 9600 9400 9200 9000>,
			<8800 8600 8400 8200 8000 7800>,
			<7600 7400 7200 7000 6800 6600>,
			<6400 6200 6000 5800 5600 5400>,
			<5200 5000 4800 4600 4400 4200>,
			<4000 3800 3600 3400 3200 3000>,
			<2800 2600 2400 2200 2000 1800>,
			<1600 1400 1200 1000 900 800>,
			<700 600 500 400 300 200>,
			<100 0>;
		qcom,lut-data = <16732 16675 16558 16492 16474 16448>,
			<16803 16688 16576 16499 16473 16452>,
			<16900 16707 16594 16506 16473 16456>,
			<17002 16731 16613 16515 16476 16459>,
			<17088 16760 16631 16524 16479 16462>,
			<17139 16793 16651 16533 16483 16465>,
			<17158 16832 16671 16544 16490 16466>,
			<17170 16877 16691 16555 16497 16467>,
			<17171 16910 16708 16565 16502 16470>,
			<17139 16932 16722 16575 16506 16476>,
			<17094 16949 16738 16583 16509 16484>,
			<17064 16964 16765 16591 16513 16491>,
			<17039 16979 16810 16608 16524 16498>,
			<17030 16992 16854 16627 16538 16503>,
			<17025 17002 16892 16642 16557 16510>,
			<17020 17007 16927 16659 16575 16522>,
			<17016 16985 16954 16683 16589 16538>,
			<17012 16910 16975 16716 16602 16560>,
			<17010 16839 16977 16754 16619 16579>,
			<17011 16800 16915 16799 16645 16596>,
			<17015 16778 16786 16833 16673 16612>,
			<17021 16772 16697 16826 16690 16626>,
			<17027 16771 16658 16733 16672 16621>,
			<17035 16771 16645 16622 16629 16591>,
			<17045 16773 16646 16568 16554 16527>,
			<17058 16781 16650 16548 16504 16483>,
			<17073 16793 16658 16553 16503 16480>,
			<17088 16808 16671 16559 16507 16486>,
			<17102 16825 16688 16566 16515 16496>,
			<17120 16846 16707 16578 16532 16509>,
			<17141 16873 16726 16595 16552 16524>,
			<17164 16904 16746 16611 16569 16538>,
			<17187 16934 16767 16626 16583 16553>,
			<17206 16965 16788 16642 16590 16566>,
			<17217 16998 16810 16659 16593 16574>,
			<17219 17033 16832 16679 16591 16571>,
			<17208 17072 16856 16697 16584 16551>,
			<17181 17111 16882 16706 16573 16526>,
			<17144 17136 16902 16699 16564 16518>,
			<17109 17147 16913 16675 16557 16515>,
			<17104 17136 16912 16653 16553 16513>,
			<17172 17052 16881 16638 16551 16508>,
			<17363 16920 16817 16621 16544 16503>,
			<17650 16907 16752 16594 16529 16501>,
			<18227 16958 16704 16579 16517 16496>,
			<19812 17138 16770 16601 16524 16501>,
			<20837 17257 16832 16635 16548 16508>,
			<22749 17579 16928 16678 16575 16519>,
			<25653 18156 17069 16717 16583 16528>,
			<29582 18997 17183 16754 16583 16536>,
			<34995 20224 17251 16759 16581 16527>,
			<43292 22099 17393 16709 16561 16503>,
			<54506 24925 17790 16740 16598 16538>,
			<65535 29723 18830 16925 16796 16683>,
			<65535 29723 18830 16925 16796 16683>,
			<65535 29723 18830 16925 16796 16683>;
	};

	qcom,pc-temp-y5-lut {
		qcom,lut-col-legend = <(-10) 0 10 25 40 50>;
		qcom,lut-row-legend = <10000 9800 9600 9400 9200 9000>,
			<8800 8600 8400 8200 8000 7800>,
			<7600 7400 7200 7000 6800 6600>,
			<6400 6200 6000 5800 5600 5400>,
			<5200 5000 4800 4600 4400 4200>,
			<4000 3800 3600 3400 3200 3000>,
			<2800 2600 2400 2200 2000 1800>,
			<1600 1400 1200 1000 900 800>,
			<700 600 500 400 300 200>,
			<100 0>;
		qcom,lut-data = <12741 12574 13176 15356 15493 19335>,
			<12008 12318 12957 14812 15115 18600>,
			<11555 12066 12564 14271 14735 17564>,
			<11313 11829 12116 13761 14362 16463>,
			<11216 11622 11732 13307 14005 15533>,
			<11198 11459 11531 12934 13674 15011>,
			<11476 11328 11513 12622 13340 14864>,
			<12115 11222 11516 12338 13011 14776>,
			<12565 11194 11532 12141 12822 14599>,
			<12873 11307 11578 12110 12973 14123>,
			<13052 11539 11615 12199 13226 13649>,
			<13034 11999 11560 12225 13292 13429>,
			<12876 12876 11371 12050 13157 13486>,
			<12703 13884 11271 11900 12831 13647>,
			<12451 15197 11490 11919 12287 13610>,
			<12270 16304 12008 11940 11915 13324>,
			<12295 16485 12917 11878 11921 12796>,
			<12352 16074 14590 11746 11989 12177>,
			<12421 15437 15871 11729 12048 11972>,
			<12529 14676 16205 12302 12228 12250>,
			<12614 13820 16218 13595 12640 12796>,
			<12640 13220 15778 14844 13906 13642>,
			<12696 12883 14549 15795 16171 14626>,
			<12777 12781 13377 15877 17127 14833>,
			<12825 12868 12986 14831 15681 14498>,
			<12853 12985 12907 13295 13607 14120>,
			<12903 13031 12898 12630 13148 13843>,
			<13053 13071 12915 12776 13556 13424>,
			<13355 13151 12981 13035 13764 13095>,
			<13692 13164 13106 13070 13467 13060>,
			<14054 13099 13263 12940 13206 13109>,
			<14476 13069 13415 12943 13257 13344>,
			<14918 13139 13545 13154 13461 13787>,
			<15284 13271 13618 13340 13679 14146>,
			<15566 13410 13671 13480 13922 14413>,
			<15816 13545 13753 13615 14127 14664>,
			<16049 13715 13859 13826 14211 14744>,
			<16183 13958 13945 14076 14052 14416>,
			<16084 14428 14014 14237 13649 13873>,
			<15218 15037 14152 14153 13142 13620>,
			<13781 15354 14265 13770 12752 13670>,
			<12070 15325 14106 13083 12544 13878>,
			<10774 15047 13660 12573 12629 13866>,
			<10368 13606 13008 12544 13100 13103>,
			<10094 11320 12197 12570 13492 13127>,
			<9612 10835 11686 12155 13248 12903>,
			<9398 10669 11370 11818 12546 13661>,
			<9239 10371 11110 11732 11952 13439>,
			<9127 10039 10816 11648 12262 13090>,
			<9056 9771 10783 11343 12536 12878>,
			<9011 9560 10848 11305 12315 13337>,
			<8954 9346 10827 11856 12806 15456>,
			<8900 9195 10560 13352 15192 16626>,
			<8848 9088 10232 16236 17248 17468>,
			<8848 9088 10232 16236 17248 17468>,
			<8848 9088 10232 16236 17248 17468>;
	};

	qcom,pc-temp-y6-lut {
		qcom,lut-col-legend = <(-10) 0 10 25 40 50>;
		qcom,lut-row-legend = <10000 9800 9600 9400 9200 9000>,
			<8800 8600 8400 8200 8000 7800>,
			<7600 7400 7200 7000 6800 6600>,
			<6400 6200 6000 5800 5600 5400>,
			<5200 5000 4800 4600 4400 4200>,
			<4000 3800 3600 3400 3200 3000>,
			<2800 2600 2400 2200 2000 1800>,
			<1600 1400 1200 1000 900 800>,
			<700 600 500 400 300 200>,
			<100 0>;
		qcom,lut-data = <5433 5228 5136 5059 5041 5039>,
			<5451 5227 5130 5060 5040 5037>,
			<5467 5230 5129 5062 5040 5036>,
			<5482 5235 5130 5065 5041 5036>,
			<5497 5241 5134 5068 5043 5037>,
			<5509 5249 5139 5072 5045 5039>,
			<5521 5259 5146 5077 5048 5041>,
			<5532 5271 5156 5082 5052 5044>,
			<5534 5281 5166 5087 5056 5047>,
			<5522 5289 5173 5092 5059 5050>,
			<5505 5296 5181 5097 5063 5052>,
			<5490 5307 5189 5102 5067 5055>,
			<5475 5321 5198 5108 5071 5059>,
			<5463 5331 5208 5114 5075 5062>,
			<5454 5338 5220 5120 5079 5066>,
			<5448 5342 5235 5127 5083 5070>,
			<5446 5335 5248 5134 5088 5073>,
			<5446 5308 5259 5143 5093 5077>,
			<5445 5279 5261 5154 5100 5082>,
			<5447 5260 5241 5170 5111 5090>,
			<5449 5245 5198 5184 5123 5099>,
			<5450 5237 5165 5181 5129 5105>,
			<5452 5233 5145 5146 5121 5100>,
			<5456 5232 5136 5105 5103 5085>,
			<5458 5233 5135 5082 5071 5060>,
			<5461 5236 5135 5071 5049 5043>,
			<5465 5240 5137 5071 5048 5042>,
			<5471 5245 5142 5073 5051 5043>,
			<5481 5251 5148 5077 5055 5046>,
			<5492 5259 5155 5081 5059 5050>,
			<5504 5268 5163 5086 5064 5055>,
			<5518 5278 5171 5091 5069 5060>,
			<5533 5290 5179 5098 5074 5067>,
			<5546 5303 5188 5104 5078 5072>,
			<5557 5317 5196 5111 5079 5074>,
			<5568 5332 5206 5119 5079 5074>,
			<5578 5349 5217 5126 5078 5068>,
			<5589 5368 5228 5130 5075 5060>,
			<5603 5389 5238 5129 5071 5056>,
			<5628 5406 5247 5124 5068 5056>,
			<5674 5414 5250 5117 5067 5057>,
			<5781 5410 5243 5111 5068 5058>,
			<6042 5408 5231 5106 5067 5057>,
			<6646 5460 5226 5100 5066 5055>,
			<8091 5663 5233 5099 5065 5053>,
			<11444 6235 5332 5120 5072 5058>,
			<13739 6657 5421 5140 5083 5067>,
			<17352 7513 5561 5168 5094 5074>,
			<22259 8815 5770 5196 5105 5080>,
			<28061 10365 6043 5220 5113 5084>,
			<34587 12195 6403 5235 5111 5082>,
			<42270 14518 7001 5240 5107 5078>,
			<49798 17068 7724 5299 5133 5095>,
			<55755 19580 8693 5430 5207 5144>,
			<55755 19580 8693 5430 5207 5144>,
			<55755 19580 8693 5430 5207 5144>;
	};

};
